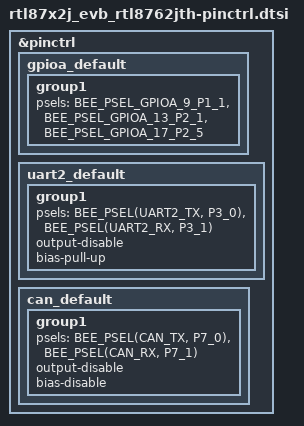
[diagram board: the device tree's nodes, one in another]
/*
 * Copyright(c) 2026, Realtek Semiconductor Corporation
 * SPDX-License-Identifier: Apache-2.0
 */

#include <dt-bindings/pinctrl/rtl87x2j-pinctrl.h>

&pinctrl {
	gpioa_default: gpioa_default {
		group1 {
			psels = <BEE_PSEL_GPIOA_9_P1_1>,
				<BEE_PSEL_GPIOA_13_P2_1>,
				<BEE_PSEL_GPIOA_17_P2_5>;
		};
	};

	uart2_default: uart2_default {
		group1 {
			psels = <BEE_PSEL(UART2_TX, P3_0)>,
				<BEE_PSEL(UART2_RX, P3_1)>;
			output-disable;
			bias-pull-up;
		};
	};

	can_default: can_default {
		group1 {
			psels = <BEE_PSEL(CAN_TX, P7_0)>,
				<BEE_PSEL(CAN_RX, P7_1)>;
			output-disable;
			bias-disable;
		};
	};
};
